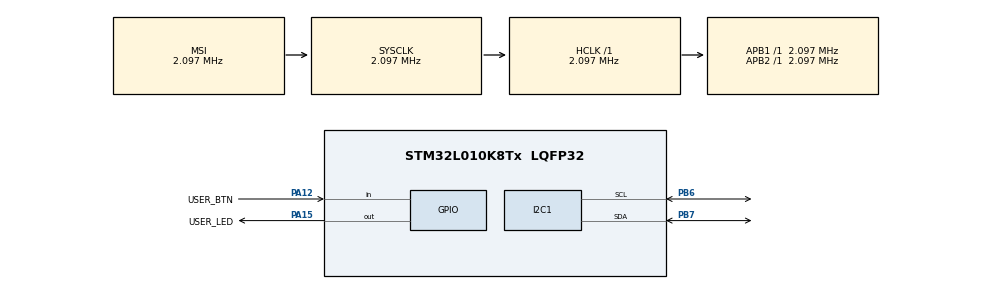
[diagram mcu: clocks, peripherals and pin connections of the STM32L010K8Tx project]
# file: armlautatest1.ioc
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Mcu.Family=STM32L0
Mcu.Name=STM32L010K8Tx
Mcu.Package=LQFP32
PA12.GPIO_Label=USER_BTN
PA12.GPIO_PuPd=GPIO_PULLUP
PA12.Signal=GPIO_Input
PA13.Mode=Serial_Wire
PA13.Signal=SYS_SWDIO
PA14.Mode=Serial_Wire
PA14.Signal=SYS_SWCLK
PA15.GPIO_Label=USER_LED
PA15.Signal=GPIO_Output
PB6.Mode=I2C
PB6.Signal=I2C1_SCL
PB7.Mode=I2C
PB7.Signal=I2C1_SDA
ProjectManager.HeapSize=0x200
ProjectManager.StackSize=0x400
ProjectManager.TargetToolchain=STM32CubeIDE
RCC.AHBFreq_Value=2097000
RCC.APB1Freq_Value=2097000
RCC.APB1TimFreq_Value=2097000
RCC.APB2Freq_Value=2097000
RCC.APB2TimFreq_Value=2097000
RCC.HSI16_VALUE=16000000
RCC.HSI_VALUE=16000000
RCC.LSE_VALUE=32768
RCC.MSI_VALUE=2097000
RCC.SYSCLKFreq_VALUE=2097000
RCC.VCOOutputFreq_Value=48000000
board=custom

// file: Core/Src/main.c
/* USER CODE BEGIN Header */
/**
  ******************************************************************************
  * @file           : main.c
  * @brief          : Main program body
  ******************************************************************************
  * @attention
  *
  * <h2><center>&copy; Copyright (c) 2020 STMicroelectronics.
  * All rights reserved.</center></h2>
  *
  * This software component is licensed by ST under BSD 3-Clause license,
  * the "License"; You may not use this file except in compliance with the
  * License. You may obtain a copy of the License at:
  *                        opensource.org/licenses/BSD-3-Clause
  *
  ******************************************************************************
  */
/* USER CODE END Header */

#include "main.h"

I2C_HandleTypeDef hi2c1;

void SystemClock_Config(void);
static void MX_GPIO_Init(void);
static void MX_I2C1_Init(void);

int main(void)
{
  /* USER CODE BEGIN 1 */
uint32_t blinkDelay;
  /* USER CODE END 1 */

  /* MCU Configuration--------------------------------------------------------*/

  /* Reset of all peripherals, Initializes the Flash interface and the Systick. */
  HAL_Init();

  /* Configure the system clock */
  SystemClock_Config();

  /* Initialize all configured peripherals */
  MX_GPIO_Init();
  MX_I2C1_Init();

  /* Infinite loop */
  /* USER CODE BEGIN WHILE */
  while (1)
  {
	  if ( HAL_GPIO_ReadPin(USER_BTN_GPIO_Port, USER_BTN_Pin) == GPIO_PIN_RESET) blinkDelay = 50;
	  else blinkDelay = 250;
	  HAL_GPIO_WritePin(USER_LED_GPIO_Port, USER_LED_Pin, GPIO_PIN_SET);
	  HAL_Delay(50);
	  HAL_GPIO_WritePin(USER_LED_GPIO_Port, USER_LED_Pin, GPIO_PIN_RESET);
	  HAL_Delay(blinkDelay);
    /* USER CODE END WHILE */

  }
}

void SystemClock_Config(void)
{
  RCC_OscInitTypeDef RCC_OscInitStruct = {0};
  RCC_ClkInitTypeDef RCC_ClkInitStruct = {0};
  RCC_PeriphCLKInitTypeDef PeriphClkInit = {0};

  /** Configure the main internal regulator output voltage
  */
  __HAL_PWR_VOLTAGESCALING_CONFIG(PWR_REGULATOR_VOLTAGE_SCALE1);
  /** Initializes the CPU, AHB and APB busses clocks
  */
  RCC_OscInitStruct.OscillatorType = RCC_OSCILLATORTYPE_MSI;
  RCC_OscInitStruct.MSIState = RCC_MSI_ON;
  RCC_OscInitStruct.MSICalibrationValue = 0;
  RCC_OscInitStruct.MSIClockRange = RCC_MSIRANGE_5;
  RCC_OscInitStruct.PLL.PLLState = RCC_PLL_NONE;
  if (HAL_RCC_OscConfig(&RCC_OscInitStruct) != HAL_OK)
  {
    Error_Handler();
  }
  /** Initializes the CPU, AHB and APB busses clocks
  */
  RCC_ClkInitStruct.ClockType = RCC_CLOCKTYPE_HCLK|RCC_CLOCKTYPE_SYSCLK
                              |RCC_CLOCKTYPE_PCLK1|RCC_CLOCKTYPE_PCLK2;
  RCC_ClkInitStruct.SYSCLKSource = RCC_SYSCLKSOURCE_MSI;
  RCC_ClkInitStruct.AHBCLKDivider = RCC_SYSCLK_DIV1;
  RCC_ClkInitStruct.APB1CLKDivider = RCC_HCLK_DIV1;
  RCC_ClkInitStruct.APB2CLKDivider = RCC_HCLK_DIV1;

  if (HAL_RCC_ClockConfig(&RCC_ClkInitStruct, FLASH_LATENCY_0) != HAL_OK)
  {
    Error_Handler();
  }
  PeriphClkInit.PeriphClockSelection = RCC_PERIPHCLK_I2C1;
  PeriphClkInit.I2c1ClockSelection = RCC_I2C1CLKSOURCE_PCLK1;
  if (HAL_RCCEx_PeriphCLKConfig(&PeriphClkInit) != HAL_OK)
  {
    Error_Handler();
  }
}

static void MX_I2C1_Init(void)
{

  hi2c1.Instance = I2C1;
  hi2c1.Init.Timing = 0x00000708;
  hi2c1.Init.OwnAddress1 = 0;
  hi2c1.Init.AddressingMode = I2C_ADDRESSINGMODE_7BIT;
  hi2c1.Init.DualAddressMode = I2C_DUALADDRESS_DISABLE;
  hi2c1.Init.OwnAddress2 = 0;
  hi2c1.Init.OwnAddress2Masks = I2C_OA2_NOMASK;
  hi2c1.Init.GeneralCallMode = I2C_GENERALCALL_DISABLE;
  hi2c1.Init.NoStretchMode = I2C_NOSTRETCH_DISABLE;
  if (HAL_I2C_Init(&hi2c1) != HAL_OK)
  {
    Error_Handler();
  }
  /** Configure Analogue filter
  */
  if (HAL_I2CEx_ConfigAnalogFilter(&hi2c1, I2C_ANALOGFILTER_ENABLE) != HAL_OK)
  {
    Error_Handler();
  }
  /** Configure Digital filter
  */
  if (HAL_I2CEx_ConfigDigitalFilter(&hi2c1, 0) != HAL_OK)
  {
    Error_Handler();
  }

}

static void MX_GPIO_Init(void)
{
  GPIO_InitTypeDef GPIO_InitStruct = {0};

  /* GPIO Ports Clock Enable */
  __HAL_RCC_GPIOA_CLK_ENABLE();
  __HAL_RCC_GPIOB_CLK_ENABLE();

  /*Configure GPIO pin Output Level */
  HAL_GPIO_WritePin(USER_LED_GPIO_Port, USER_LED_Pin, GPIO_PIN_RESET);

  /*Configure GPIO pin : USER_BTN_Pin */
  GPIO_InitStruct.Pin = USER_BTN_Pin;
  GPIO_InitStruct.Mode = GPIO_MODE_INPUT;
  GPIO_InitStruct.Pull = GPIO_PULLUP;
  HAL_GPIO_Init(USER_BTN_GPIO_Port, &GPIO_InitStruct);

  /*Configure GPIO pin : USER_LED_Pin */
  GPIO_InitStruct.Pin = USER_LED_Pin;
  GPIO_InitStruct.Mode = GPIO_MODE_OUTPUT_PP;
  GPIO_InitStruct.Pull = GPIO_NOPULL;
  GPIO_InitStruct.Speed = GPIO_SPEED_FREQ_LOW;
  HAL_GPIO_Init(USER_LED_GPIO_Port, &GPIO_InitStruct);

}

void Error_Handler(void)
{
}

/************************ (C) COPYRIGHT STMicroelectronics *****END OF FILE****/
